# STM32WBA55 register map
File version: 1.0
CPU: CM33 r0p1, little endian, MPU, FPU, 4 interrupt priority bits
Registers are 32-bit, read-write, reset 0x0 unless marked. A register's access mark holds for its fields unless they carry their own. Offsets are from the block's base; [hi:lo] are bit positions; {n}, {i} and the like mark numbered series; 'fields as' and 'values as' point back to an identical list.

## RAMCFG — RAMs configuration controller
Base 0x40026000
Same registers: SEC_RAMCFG 0x50026000
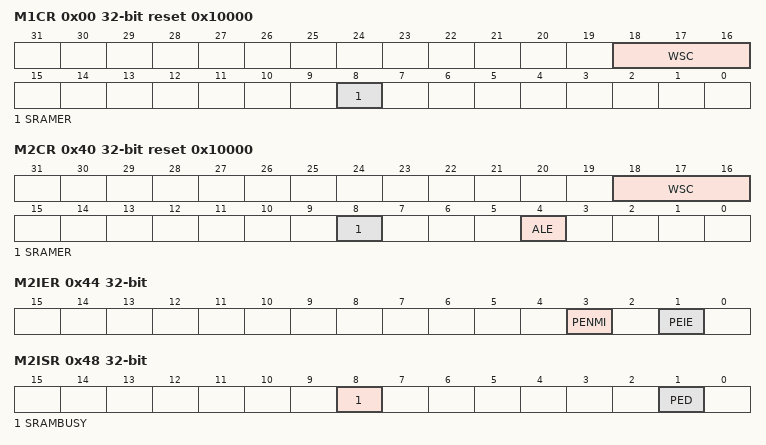
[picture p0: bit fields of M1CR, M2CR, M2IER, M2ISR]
0x00 M1CR reset 0x10000 — RAMCFG SRAM1 control register
  [18:16] WSC — SRAM1 wait state configuration This field is used to program the number of wait states inserted on the AHB when reading the SRAM1, depending on its access time. ... Note: Before entering Stop 1 mode software must set SRAM1 wait states to at least 1.
  [8] SRAMER — SRAM1 erase This bit can be set by software only after writing the unlock sequence in the ERASEKEY field of the RAMCFG_M1ERKEYR register. Setting this bit starts the SRAM1 erase. This bit is automatically cleared by hardware at the end of the erase operation.
0x08 M1ISR ro — RAMCFG SRAM1 interrupt status register
  [8] SRAMBUSY — SRAM busy with erase operation. Note: Depending on the SRAM, the erase operation can be performed due to software request, system reset if the enabled by user option, tamper detection or RDP regression. Refer to Table38.
0x28 M1ERKEYR wo — RAMCFG SRAM1 erase key register
  [7:0] ERASEKEY — Erase write protection key The following steps are required to unlock the write protection of the SRAMER bit in the RAMCFG_MxCR register. Write 0xCA into ERASEKEY[7:0] Write 0x53 into ERASEKEY[7:0] Note: Writing a wrong key reactivates the write protection.
0x40 M2CR reset 0x10000 — RAMCFG SRAM2 control register
  [18:16] WSC — SRAM2 wait state configuration This field is used to program the number of wait states inserted on the AHB when reading the SRAM2, depending on its access time. ... Note: Before entering Stop 1 mode software must set SRAM2 wait states to at least 1.
  [8] SRAMER — SRAM2 erase This bit can be set by software only after writing the unlock sequence in the ERASEKEY field of the RAMCFG_M2ERKEYR register. Setting this bit starts the SRAM2 erase. This bit is automatically cleared by hardware at the end of the erase operation.
  [4] ALE — SRAM2 parity fail address latch enable
0x44 M2IER — RAMCFG SRAM2 interrupt enable register
  [3] PENMI — Parity error NMI. This bit is set by software and cleared only by a global RAMCFG reset Note: When PENMI bit is set, the RAMCFG maskable interrupt is not generated for a parity error whatever PEIE bit value.
  [1] PEIE — Parity error interrupt enable
0x48 M2ISR ro — RAMCFG SRAM2 interrupt status register
  [8] SRAMBUSY — SRAM2 busy with erase operation. Note: Depending on the SRAM2, the erase operation can be performed due to software request, system reset if the enabled by user option, tamper detection or RDP regression. Refer to Table38.
  [1] PED — Parity error detected
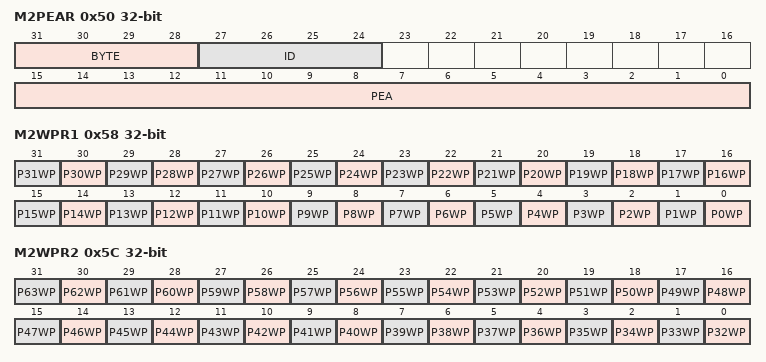
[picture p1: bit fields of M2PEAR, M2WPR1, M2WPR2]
0x50 M2PEAR ro — RAMCFG SRAM2 parity error address register
  [31:28] BYTE — Byte parity error flag. When ALE bit is set in RAMCFG_M2CR register, this field is updated when PED and CPED are zero and a new parity error is detected, with: 1xxx: parity error detected on fourth byte in word aligned address x1xx: parity error detected on third byte in word aligned address xx1x: parity error detected on second byte in word aligned address xxx1: parity error detected on first byte in word aligned address
  [27:24] ID — Parity error AHB bus master ID. When ALE bit is set in RAMCFG_M2CR register, this field is updated when PED and CPED are zero and a new parity error is detected, with: Others: reserved
  [15:0] PEA — Parity error SRAM word aligned address offset.PEA[1:0] read 0b00. When ALE bit is set in RAMCFG_M2CR register, this field is updated when PED and CPED are zero and a new parity error is detected, with the SRAM word aligned address offset corresponding to the parity error.
0x54 M2ICR — RAMCFG SRAM2 interrupt clear register
  [1] CPED — Clear parity error detect bit Writing 1 to this bit clears the PED bit in RAMCFG_M2ISR. Reading this bit returns the value of the RAMCFG_M2ISR PED bit.
0x58 M2WPR1 — RAMCFG SRAM2 write protection register 1
  [n] P{n}WP (n=0..31) — SRAM2 1-Kbyte write protect page y write protection These bits are set by software and cleared only by a system reset.
0x5C M2WPR2 — RAMCFG SRAM2 write protection register 2
  [n-32] P{n}WP (n=32..63) — SRAM2 1-Kbyte write protect page y write protection These bits are set by software and cleared only by a system reset.
0x68 M2ERKEYR wo — RAMCFG SRAM2 erase key register
  fields as M1ERKEYR
